# ESP32-P4 register map
Vendor: ESPRESSIF SYSTEMS (SHANGHAI) CO., LTD.; Series: ESP32 P-Series; File version: 3
CPU: RV32IMAFC r0p0, little endian, no MPU, FPU, 0 interrupt priority bits
Address unit: 32 bits
Registers are 32-bit, read-write, reset 0x0 unless marked. A register's access mark holds for its fields unless they carry their own. Offsets are from the block's base; [hi:lo] are bit positions; {n}, {i} and the like mark numbered series; 'fields as' and 'values as' point back to an identical list.

## LP_GPIO — Low-power General Purpose Input/Output
Base 0x5012A000
0x00 CLK_EN reset 0x1 — Reserved
  [0] REG_CLK_EN
0x04 VER_DATE reset 0x230323 — Reserved
  [27:0] REG_VER_DATE
0x08 OUT — Reserved
  [15:0] REG_GPIO_OUT_DATA
0x0C OUT_W1TS wo — Reserved
  [15:0] REG_GPIO_OUT_DATA_W1TS
0x10 OUT_W1TC wo — Reserved
  [15:0] REG_GPIO_OUT_DATA_W1TC
0x14 ENABLE — Reserved
  [15:0] REG_GPIO_ENABLE_DATA
0x18 ENABLE_W1TS wo — Reserved
  [15:0] REG_GPIO_ENABLE_DATA_W1TS
0x1C ENABLE_W1TC wo — Reserved
  [15:0] REG_GPIO_ENABLE_DATA_W1TC
0x20 STATUS — Reserved
  [15:0] REG_GPIO_STATUS_DATA
0x24 STATUS_W1TS wo — Reserved
  [15:0] REG_GPIO_STATUS_DATA_W1TS
0x28 STATUS_W1TC wo — Reserved
  [15:0] REG_GPIO_STATUS_DATA_W1TC
0x2C STATUS_NEXT ro — Reserved
  [15:0] REG_GPIO_STATUS_INTERRUPT_NEXT
0x30 IN ro — Reserved
  [15:0] REG_GPIO_IN_DATA_NEXT
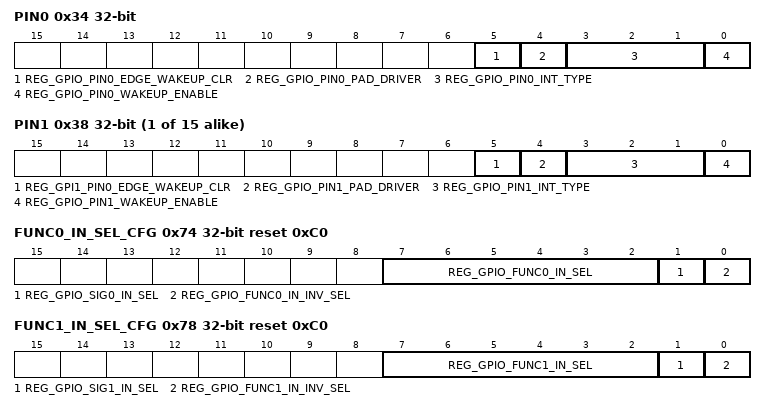
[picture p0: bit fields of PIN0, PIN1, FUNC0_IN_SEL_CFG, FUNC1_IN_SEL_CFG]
0x34 PIN0 access per field — Reserved
  [5] REG_GPIO_PIN0_EDGE_WAKEUP_CLR wo — need des
  [4] REG_GPIO_PIN0_PAD_DRIVER rw — Reserved
  [3:1] REG_GPIO_PIN0_INT_TYPE rw — Reserved
  [0] REG_GPIO_PIN0_WAKEUP_ENABLE rw — Reserved
{0x34+4i} PIN{i} access per field (i=1..15) — Reserved
  [5] REG_GPI{i}_PIN0_EDGE_WAKEUP_CLR wo — need des
  [4] REG_GPIO_PIN{i}_PAD_DRIVER rw — Reserved
  [3:1] REG_GPIO_PIN{i}_INT_TYPE rw — Reserved
  [0] REG_GPIO_PIN{i}_WAKEUP_ENABLE rw — Reserved
0x74 FUNC0_IN_SEL_CFG reset 0xC0 — Reserved
  [7:2] REG_GPIO_FUNC0_IN_SEL — reg_gpio_func0_in_sel[5:4]==2'b11->constant 1,reg_gpio_func0_in_sel[5:4]==2'b10->constant 0
  [1] REG_GPIO_SIG0_IN_SEL — Reserved
  [0] REG_GPIO_FUNC0_IN_INV_SEL — Reserved
0x78 FUNC1_IN_SEL_CFG reset 0xC0 — Reserved
  [7:2] REG_GPIO_FUNC1_IN_SEL — Reserved
  [1] REG_GPIO_SIG1_IN_SEL — Reserved
  [0] REG_GPIO_FUNC1_IN_INV_SEL — Reserved
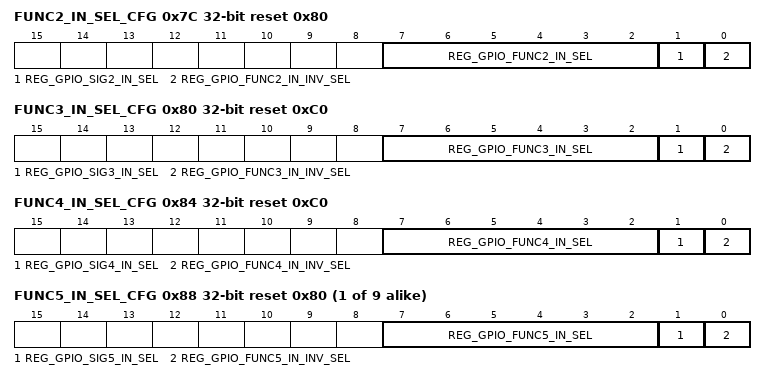
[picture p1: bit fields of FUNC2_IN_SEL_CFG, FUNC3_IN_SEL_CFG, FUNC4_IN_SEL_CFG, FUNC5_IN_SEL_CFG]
0x7C FUNC2_IN_SEL_CFG reset 0x80 — Reserved
  [7:2] REG_GPIO_FUNC2_IN_SEL — Reserved
  [1] REG_GPIO_SIG2_IN_SEL — Reserved
  [0] REG_GPIO_FUNC2_IN_INV_SEL — Reserved
0x80 FUNC3_IN_SEL_CFG reset 0xC0 — Reserved
  [7:2] REG_GPIO_FUNC3_IN_SEL — Reserved
  [1] REG_GPIO_SIG3_IN_SEL — Reserved
  [0] REG_GPIO_FUNC3_IN_INV_SEL — Reserved
0x84 FUNC4_IN_SEL_CFG reset 0xC0 — Reserved
  [7:2] REG_GPIO_FUNC4_IN_SEL — Reserved
  [1] REG_GPIO_SIG4_IN_SEL — Reserved
  [0] REG_GPIO_FUNC4_IN_INV_SEL — Reserved
{0x74+4i} FUNC{i}_IN_SEL_CFG reset 0x80 (i=5..13) — Reserved
  [7:2] REG_GPIO_FUNC{i}_IN_SEL — Reserved
  [1] REG_GPIO_SIG{i}_IN_SEL — Reserved
  [0] REG_GPIO_FUNC{i}_IN_INV_SEL — Reserved
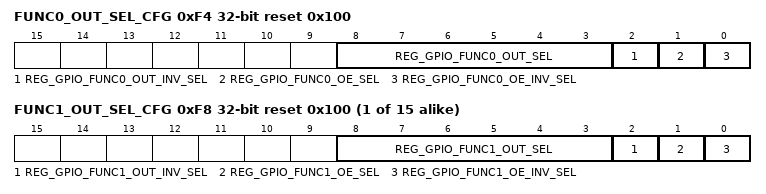
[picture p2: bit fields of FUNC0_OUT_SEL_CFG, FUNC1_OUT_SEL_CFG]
0xF4 FUNC0_OUT_SEL_CFG reset 0x100 — Reserved
  [8:3] REG_GPIO_FUNC0_OUT_SEL — reg_gpio_func0_out_sel[5:1]==16 -> output gpio register value to pad
  [2] REG_GPIO_FUNC0_OUT_INV_SEL — Reserved
  [1] REG_GPIO_FUNC0_OE_SEL — Reserved
  [0] REG_GPIO_FUNC0_OE_INV_SEL — Reserved
{0xF4+4i} FUNC{i}_OUT_SEL_CFG reset 0x100 (i=1..15) — Reserved
  [8:3] REG_GPIO_FUNC{i}_OUT_SEL — Reserved
  [2] REG_GPIO_FUNC{i}_OUT_INV_SEL — Reserved
  [1] REG_GPIO_FUNC{i}_OE_SEL — Reserved
  [0] REG_GPIO_FUNC{i}_OE_INV_SEL — Reserved

## LP_IO_MUX — Low-power Input/Output Multiplexer
Base 0x5012B000
0x00 CLK_EN reset 0x1 — Reserved
  [0] REG_CLK_EN
0x04 VER_DATE reset 0x230313 — Reserved
  [27:0] REG_VER_DATE
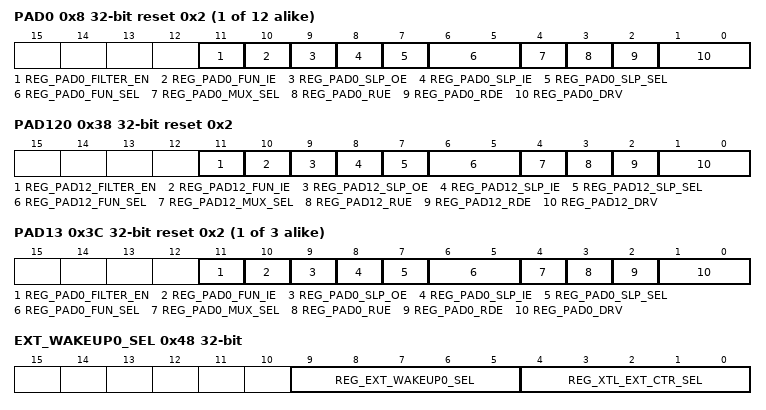
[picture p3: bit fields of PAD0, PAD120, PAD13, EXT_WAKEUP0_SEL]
{0x8+4i} PAD{i} reset 0x2 (i=0..11) — Reserved
  [11] REG_PAD{i}_FILTER_EN — need des
  [10] REG_PAD{i}_FUN_IE — input enable in work mode
  [9] REG_PAD{i}_SLP_OE — output enable in sleep mode
  [8] REG_PAD{i}_SLP_IE — input enable in sleep mode
  [7] REG_PAD{i}_SLP_SEL — 1: enable sleep mode during sleep,0: no sleep mode
  [6:5] REG_PAD{i}_FUN_SEL — function sel
  [4] REG_PAD{i}_MUX_SEL — 1:use LP GPIO,0: use digital GPIO
  [3] REG_PAD{i}_RUE — Reserved
  [2] REG_PAD{i}_RDE — Reserved
  [1:0] REG_PAD{i}_DRV — Reserved
0x38 PAD120 reset 0x2 — Reserved
  [11] REG_PAD12_FILTER_EN — need des
  [10] REG_PAD12_FUN_IE — input enable in work mode
  [9] REG_PAD12_SLP_OE — output enable in sleep mode
  [8] REG_PAD12_SLP_IE — input enable in sleep mode
  [7] REG_PAD12_SLP_SEL — 1: enable sleep mode during sleep,0: no sleep mode
  [6:5] REG_PAD12_FUN_SEL — function sel
  [4] REG_PAD12_MUX_SEL — 1:use LP GPIO,0: use digital GPIO
  [3] REG_PAD12_RUE — Reserved
  [2] REG_PAD12_RDE — Reserved
  [1:0] REG_PAD12_DRV — Reserved
{0x8+4i} PAD{i} reset 0x2 (i=13..15) — Reserved
  fields as PAD0
0x48 EXT_WAKEUP0_SEL — Reserved
  [9:5] REG_EXT_WAKEUP0_SEL — Reserved
  [4:0] REG_XTL_EXT_CTR_SEL — select LP GPIO 0 ~ 15 to control XTAL
0x4C LP_PAD_HOLD — Reserved
  [15:0] REG_LP_GPIO_HOLD
0x50 LP_PAD_HYS — Reserved
  [15:0] REG_LP_GPIO_HYS
